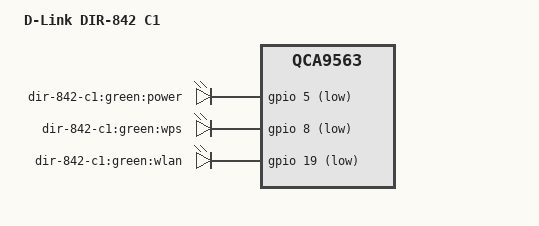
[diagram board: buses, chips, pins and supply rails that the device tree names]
// SPDX-License-Identifier: GPL-2.0-or-later OR MIT
/dts-v1/;

#include "qca9563_dlink_dir-842-c.dtsi"

/ {
	compatible = "dlink,dir-842-c1", "qca,qca9563";
	model = "D-Link DIR-842 C1";

	aliases {
		led-boot = &led_power;
		led-failsafe = &led_power;
		led-running = &led_power;
		led-upgrade = &led_power;
	};

	leds {
		compatible = "gpio-leds";

		led_power: power {
			label = "dir-842-c1:green:power";
			gpios = <&gpio 5 GPIO_ACTIVE_LOW>;
		};

		wps {
			label = "dir-842-c1:green:wps";
			gpios = <&gpio 8 GPIO_ACTIVE_LOW>;
		};

		wlan {
			label = "dir-842-c1:green:wlan";
			gpios = <&gpio 19 GPIO_ACTIVE_LOW>;
			linux,default-trigger = "phy0tpt";
		};
	};
};
